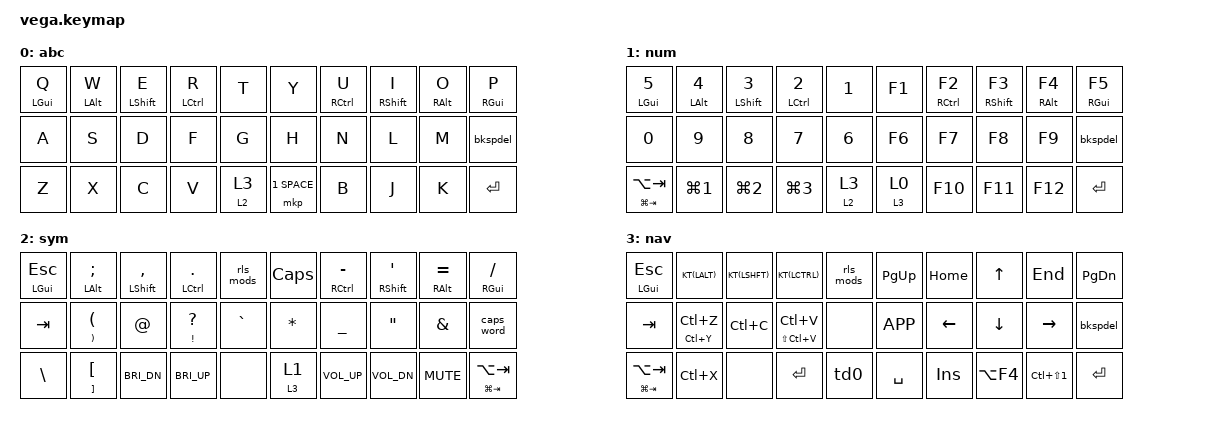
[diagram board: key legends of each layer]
#include <behaviors.dtsi>
#include <dt-bindings/zmk/keys.h>
#include <dt-bindings/zmk/bt.h>

#define ARCHIVE &kp LC(LS(N1))
#define APPLAUNCHER &kp LG(TAB)
#define SWITCHAPP &hm LG(TAB) LA(TAB)
#define KT(mod) &hold_tog mod mod

&caps_word {
    continue-list = <MINUS UNDERSCORE BKSP DEL LEFT RIGHT DOT COMMA SEMI SLASH>;
};

/ { 
    behaviors {
        mto: mom_to_layers {
            compatible = "zmk,behavior-hold-tap";
            label = "MOM_TO_LAYERS";
            #binding-cells = <2>;
            flavor = "tap-preferred";
            tapping-term-ms = <250>;
            bindings = <&mo>, <&to>;
        };
        mkp: mom_key_press {
            compatible = "zmk,behavior-hold-tap";
            label = "MOM_KEY_PRESS";
            #binding-cells = <2>;
            flavor = "tap-preferred";
            tapping-term-ms = <250>;
            quick-tap-ms = <200>;
            global-quick-tap;
            bindings = <&mo>, <&kp>;
        };        
        hm: home_mod {
            compatible = "zmk,behavior-hold-tap";
            label = "HOME_MOD";
            #binding-cells = <2>;
            flavor = "balanced";
            tapping-term-ms = <200>;
            quick-tap-ms = <150>;
            global-quick-tap;
            bindings = <&kp>, <&kp>;
        };
        hold_tog: hold_toggle {
            compatible = "zmk,behavior-hold-tap";
            label = "HOLD_TOGGLE";
            #binding-cells = <2>;
            flavor = "balanced";
            tapping-term-ms = <200>;
            quick-tap-ms = <150>;
            global-quick-tap;
            bindings = <&kp>, <&kt>;
        };

        bkspdel: backspace_delete {
            compatible = "zmk,behavior-mod-morph";
            label = "BACKSPACE_DELETE";
            #binding-cells = <0>;
            bindings = <&kp BKSP>, <&kp DEL>;
            mods = <(MOD_LGUI|MOD_LSFT|MOD_RSFT)>;
        };

        td0: tap_dance_0 {
            compatible = "zmk,behavior-tap-dance";
            label = "TAP_DANCE_0";
            #binding-cells = <0>;
            tapping-term-ms = <300>;
            bindings = <&tog 3>, <&to 0>;
        };
    };
    macros {
        rls_mods: rls_mods {
            compatible = "zmk,behavior-macro";
            label = "ZM_rls_mods";
            #binding-cells = <0>;
            wait-ms = <5>;
            tap-ms = <15>;
            bindings = <&macro_release &kp LSHFT &kp LCTRL &kp LALT &kp LGUI>;
        };
    };
    combos {    
        compatible = "zmk,combos";
        combo_bluetooth_next {
            timeout-ms = <90>;
            key-positions = <21 22 23>;
            bindings = <&bt BT_NXT>;
            layers = <0>;
        };
        combo_bluetooth_clear {
            timeout-ms = <90>;
            key-positions = <26 27 28>;
            bindings = <&bt BT_CLR>;
            layers = <0>;
        };
    };
 
    keymap {
        compatible = "zmk,keymap";
        // 0  1  2  3  4    5  6  7  8  9  
        // 10 11 12 13 14   15 16 17 18 19 
        // 20 21 22 23 24   25 26 27 28 29
        abc {
            bindings = <
                &hm LGUI Q  &hm LALT W  &hm LSHFT E  &hm LCTL R  &kp T        &kp Y         &hm RCTL U  &hm RSHFT I  &hm RALT O  &hm RGUI P 
                &kp A       &kp S       &kp D        &kp F       &kp G        &kp H         &kp N       &kp L        &kp M       &bkspdel 
                &kp Z       &kp X       &kp C        &kp V       &mto 2 3     &mkp 1 SPACE  &kp B       &kp J        &kp K       &kp ENTER   
            >;
        };

        num {
            bindings = <
                &hm LGUI N5  &hm LALT N4  &hm LSHFT N3  &hm LCTL N2  &kp N1       &kp F1    &hm RCTL F2  &hm RSHFT F3  &hm RALT F4  &hm RGUI F5 
                &kp N0       &kp N9       &kp N8        &kp N7       &kp N6       &kp F6    &kp F7       &kp F8        &kp F9       &bkspdel   
                SWITCHAPP    &kp LG(1)    &kp LG(2)     &kp LG(3)    &mto 2 3     &mto 3 0  &kp F10      &kp F11       &kp F12      &kp ENTER 
            >;
        };    
    
        sym {
            bindings = <
                &hm LGUI ESC  &hm LALT SEMI  &hm LSHFT COMMA  &hm LCTL DOT    &rls_mods     &kp CAPS  &hm RCTL MINUS  &hm RSHFT SQT  &hm RALT EQUAL  &hm RGUI SLASH 
                &kp TAB       &hm RPAR LPAR  &kp AT           &hm EXCL QMARK  &kp GRAVE     &kp STAR  &kp UNDER       &kp DQT        &kp AMPS        &caps_word 
                &kp BSLH      &hm RBKT LBKT  &kp C_BRI_DN     &kp C_BRI_UP    &none         &mto 3 1  &kp C_VOL_UP    &kp C_VOL_DN   &kp C_MUTE      SWITCHAPP  
            >;
        };

        nav {
            bindings = <
                &hm LGUI ESC  KT(LALT)         KT(LSHFT)  KT(LCTRL)            &rls_mods     &kp PG_UP   &kp HOME  &kp UP      &kp END    &kp PG_DN  
                &kp TAB       &hm LC(Y) LC(Z)  &kp LC(C)  &hm LS(LC(V)) LC(V)  &none         &kp K_APP   &kp LEFT  &kp DOWN    &kp RIGHT  &bkspdel  
                SWITCHAPP     &kp LC(X)        &none      &kp ENTER            &td0          &kp SPACE   &kp INS   &kp LA(F4)  ARCHIVE    &kp ENTER  
            >;
        };
    
    };
};
